# STM32H7S7xx register map
File version: 1.0
Registers are 32-bit, read-write, reset 0x0 unless marked. A register's access mark holds for its fields unless they carry their own. Offsets are from the block's base; [hi:lo] are bit positions; {n}, {i} and the like mark numbered series.

## SDMMC2 — Secure Digital Card/IO Embedded MultiMediaCard Interface
Base 0x48002400
Same registers: SDMMC1 0x52007000
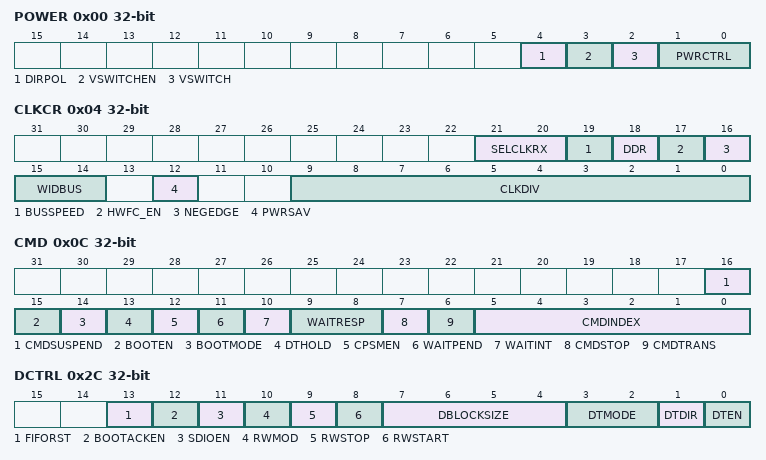
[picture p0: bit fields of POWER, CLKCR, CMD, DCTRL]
0x00 POWER — SDMMC Power control register
  [4] DIRPOL — Data and command direction signals polarity selection
  [3] VSWITCHEN — Voltage switch procedure enable
  [2] VSWITCH — Voltage switch sequence start
  [1:0] PWRCTRL — SDMMC state control bits
0x04 CLKCR — SDMMC Clock control register
  [21:20] SELCLKRX — Receive clock selection
  [19] BUSSPEED — Bus speed mode selection
  [18] DDR — Data rate signal selection
  [17] HWFC_EN — Hardware flow control enable
  [16] NEGEDGE — SDMMC_CK dephasing selection bit
  [15:14] WIDBUS — Wide bus mode enable bit
  [12] PWRSAV — Power saving configuration bit
  [9:0] CLKDIV — Clock divide factor
0x08 ARG — SDMMC Argument register
  [31:0] CMDARG — Command argument
0x0C CMD — SDMMC Command register
  [16] CMDSUSPEND — CPSM treats the command as a suspend or resume command
  [15] BOOTEN — Enable boot mode procedure
  [14] BOOTMODE — Select the boot mode procedure to be used
  [13] DTHOLD — Hold new data block transmission and reception in DPSM
  [12] CPSMEN — Command path state machine enable bit
  [11] WAITPEND — CPSM waits for end of data transfer from DPSM
  [10] WAITINT — CPSM waits for interrupt request
  [9:8] WAITRESP — Wait for response bits
  [7] CMDSTOP — CPSM treats the command as a stop transmission command
  [6] CMDTRANS — CPSM treats the command as a data transfer command
  [5:0] CMDINDEX — Command index
0x10 RESPCMD — SDMMC Command response register
  [5:0] RESPCMD — Response command index
0x14 RESP1 — SDMMC Response 1 register
  [31:0] CARDSTATUS1 — Card status [31:0] (short response) or [127:96] (long response)
{0x10+4i} RESP{i} (i=2..4) — SDMMC Response {i} register
  [31:0] CARDSTATUS{i} — Card status [{159-32i}:{128-32i}] (long response)
0x24 DTIMER — SDMMC Data timer register
  [31:0] DATATIME — Data and R1b busy timeout period
0x28 DLEN — SDMMC Data length register
  [26:0] DATALENGTH — Data length value
0x2C DCTRL — SDMMC Data control register
  [13] FIFORST — FIFO reset (flush any remaining data)
  [12] BOOTACKEN — Enable the reception of the boot acknowledgement
  [11] SDIOEN — SD I/O interrupt enable functions
  [10] RWMOD — Read wait mode
  [9] RWSTOP — Read wait stop
  [8] RWSTART — Read wait start
  [7:4] DBLOCKSIZE — Data block size
  [3:2] DTMODE — Data transfer mode selection
  [1] DTDIR — Data transfer direction selection
  [0] DTEN — Data transfer enable bit
0x30 DCOUNT — SDMMC Data counter register
  [26:0] DATACOUNT — Data count value
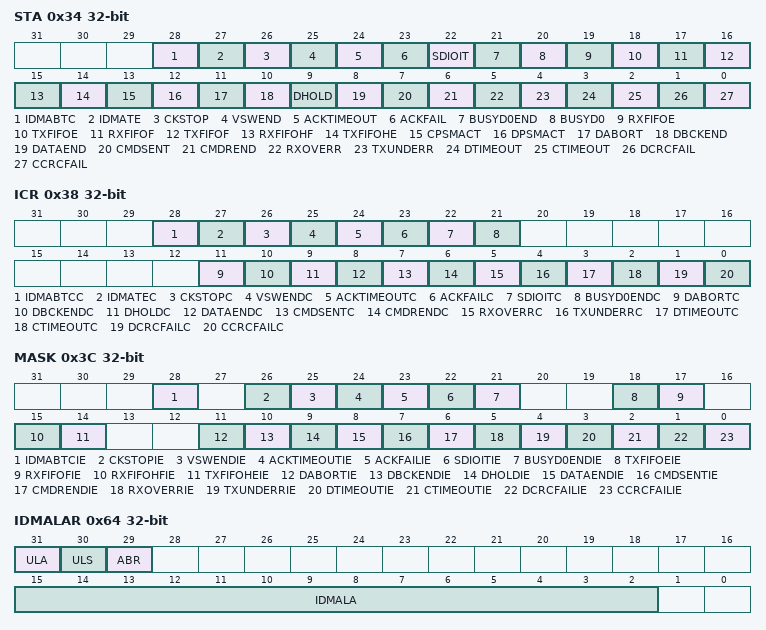
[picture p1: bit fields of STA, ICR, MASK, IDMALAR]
0x34 STA — SDMMC Status register
  [28] IDMABTC — IDMA buffer transfer complete
  [27] IDMATE — IDMA transfer error
  [26] CKSTOP — SDMMC_CK stopped in voltage switch procedure
  [25] VSWEND — Voltage switch critical timing section completion
  [24] ACKTIMEOUT — Boot acknowledgement timeout
  [23] ACKFAIL — Boot acknowledgement received (boot acknowledgement check fail)
  [22] SDIOIT — SDIO interrupt received
  [21] BUSYD0END — End of SDMMC_D0 busy following a CMD response detected
  [20] BUSYD0 — Inverted value of SDMMC_D0 line (busy)
  [19] RXFIFOE — Receive FIFO empty
  [18] TXFIFOE — Transmit FIFO empty
  [17] RXFIFOF — Receive FIFO full
  [16] TXFIFOF — Transmit FIFO full
  [15] RXFIFOHF — Receive FIFO half full
  [14] TXFIFOHE — Transmit FIFO half empty
  [13] CPSMACT — Command path state machine active
  [12] DPSMACT — Data path state machine active
  [11] DABORT — Data transfer aborted by CMD12
  [10] DBCKEND — Data block sent/received
  [9] DHOLD — Data transfer hold
  [8] DATAEND — Data transfer ended correctly
  [7] CMDSENT — Command sent (no response required)
  [6] CMDREND — Command response received (CRC check passed or no CRC)
  [5] RXOVERR — Received FIFO overrun error
  [4] TXUNDERR — Transmit FIFO underrun error
  [3] DTIMEOUT — Data timeout
  [2] CTIMEOUT — Command response timeout
  [1] DCRCFAIL — Data block sent/received (CRC check failed)
  [0] CCRCFAIL — Command response received (CRC check failed)
0x38 ICR — SDMMC Interrupt clear register
  [28] IDMABTCC — IDMA buffer transfer complete clear bit
  [27] IDMATEC — IDMA transfer error
  [26] CKSTOPC — SDMMC_CK stopped in voltage switch procedure clear bit
  [25] VSWENDC — Voltage switch critical timing section completion clear bit
  [24] ACKTIMEOUTC — Boot acknowledgement timeout clear bit
  [23] ACKFAILC — Boot acknowledgement received (boot acknowledgement check fail) clear bit
  [22] SDIOITC — SDIO interrupt received clear bit
  [21] BUSYD0ENDC — End of SDMMC_D0 busy following a CMD response detected clear bit
  [11] DABORTC — Data transfer aborted by CMD12 clear bit
  [10] DBCKENDC — Data block sent/received clear bit
  [9] DHOLDC — Data transfer hold clear bit
  [8] DATAENDC — Data transfer ended correctly clear bit
  [7] CMDSENTC — Command sent (no response required) clear bit
  [6] CMDRENDC — Command response received (CRC check passed or no CRC) clear bit
  [5] RXOVERRC — Received FIFO overrun error clear bit
  [4] TXUNDERRC — Transmit FIFO underrun error clear bit
  [3] DTIMEOUTC — Data timeout clear bit
  [2] CTIMEOUTC — Command response timeout clear bit
  [1] DCRCFAILC — Data block sent/received (CRC check failed) clear bit
  [0] CCRCFAILC — Command response received (CRC check failed) clear bit
0x3C MASK — SDMMC Mask register
  [28] IDMABTCIE — IDMA buffer transfer complete interrupt enable
  [26] CKSTOPIE — SDMMC_CK stopped in voltage switch procedure interrupt enable
  [25] VSWENDIE — Voltage switch critical timing section completion interrupt enable
  [24] ACKTIMEOUTIE — Boot acknowledgement timeout interrupt enable
  [23] ACKFAILIE — Boot acknowledgement received (boot acknowledgement check fail) interrupt enable
  [22] SDIOITIE — SDIO interrupt received interrupt enable
  [21] BUSYD0ENDIE — End of SDMMC_D0 busy following a CMD response detected interrupt enable
  [18] TXFIFOEIE — Transmit FIFO empty interrupt enable
  [17] RXFIFOFIE — Receive FIFO full interrupt enable
  [15] RXFIFOHFIE — Receive FIFO half full interrupt enable
  [14] TXFIFOHEIE — Transmit FIFO half empty interrupt enable
  [11] DABORTIE — Data transfer aborted by CMD12 interrupt enable
  [10] DBCKENDIE — Data block sent/received interrupt enable
  [9] DHOLDIE — Data transfer hold interrupt enable
  [8] DATAENDIE — Data transfer ended correctly interrupt enable
  [7] CMDSENTIE — Command sent (no response required) interrupt enable
  [6] CMDRENDIE — Command response received (CRC check passed or no CRC) interrupt enable
  [5] RXOVERRIE — Received FIFO overrun error interrupt enable
  [4] TXUNDERRIE — Transmit FIFO underrun error interrupt enable
  [3] DTIMEOUTIE — Data timeout interrupt enable
  [2] CTIMEOUTIE — Command response timeout interrupt enable
  [1] DCRCFAILIE — Data block sent/received (CRC check failed) interrupt enable
  [0] CCRCFAILIE — Command response received (CRC check failed) interrupt enable
0x40 ACKTIME — SDMMC Acknowledgement timer register
  [26:0] ACKTIME — Boot acknowledgement timeout period
0x50 IDMACTRL — SDMMC IDMA control register
0x54 IDMABSIZE — SDMMC IDMA buffer size register
  [16:5] IDMABNDT — Number of bytes per buffer
0x58 IDMABASER — SDMMC IDMA buffer base address register
  [31:0] IDMABASER — Buffer memory base address
0x64 IDMALAR — SDMMC IDMA linked list address register
  [31] ULA — Update Address from linked list
  [30] ULS — Update Size from linked list
  [29] ABR — Acknowledge linked list buffer ready
  [15:2] IDMALA — Linked list item address offset
0x68 IDMABAR — SDMMC IDMA linked list memory base register
  [31:2] IDMABAR — Linked list memory base address
0x80 FIFO — SDMMC data FIFO register
  [31:0] FIFODATA — Receive and transmit FIFO data
